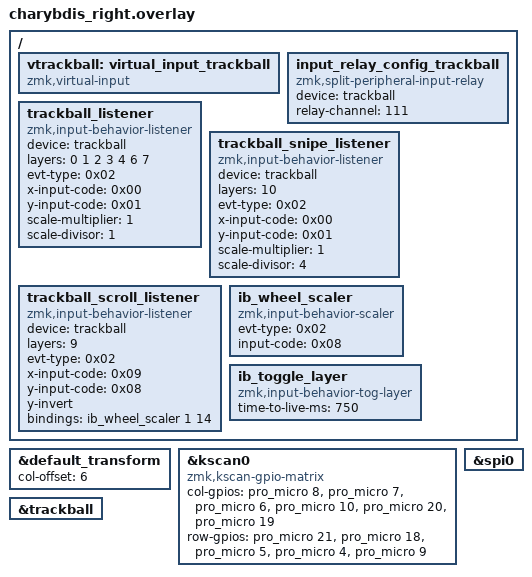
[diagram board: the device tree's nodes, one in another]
#include "charybdis.dtsi"
#include "charybdis_pmw3610.dtsi"

// The matrix transform is 6 columns over because the left half is 6 columns wide.
&default_transform {
	col-offset = <6>;
};

&kscan0 {
	compatible = "zmk,kscan-gpio-matrix";
	
	col-gpios
		= <&pro_micro 8 (GPIO_ACTIVE_HIGH | GPIO_PULL_DOWN)>
		, <&pro_micro 7 (GPIO_ACTIVE_HIGH | GPIO_PULL_DOWN)>
		, <&pro_micro 6 (GPIO_ACTIVE_HIGH | GPIO_PULL_DOWN)>
		, <&pro_micro 10 (GPIO_ACTIVE_HIGH | GPIO_PULL_DOWN)>
		, <&pro_micro 20 (GPIO_ACTIVE_HIGH | GPIO_PULL_DOWN)>
		, <&pro_micro 19 (GPIO_ACTIVE_HIGH | GPIO_PULL_DOWN)>
		;

	row-gpios
                = <&pro_micro 21  GPIO_ACTIVE_HIGH>
                , <&pro_micro 18  GPIO_ACTIVE_HIGH>
                , <&pro_micro 5  GPIO_ACTIVE_HIGH>
                , <&pro_micro 4  GPIO_ACTIVE_HIGH>
                , <&pro_micro 9 GPIO_ACTIVE_HIGH>
                ;
};

&spi0 {
    status = "okay";
};

&trackball {
    status = "okay";
};

// https://github.com/badjeff/zmk-pmw3610-driver
/ {
  vtrackball: virtual_input_trackball {
    compatible = "zmk,virtual-input";
  };

  // Relay trackball data to left side
  input_relay_config_trackball {
    compatible = "zmk,split-peripheral-input-relay";
    device = <&trackball>;
    relay-channel = <111>;
  };

  trackball_listener {
    compatible = "zmk,input-behavior-listener";
    device = <&trackball>;
    layers = <0 1 2 3 4 6 7>; // BASE LOWER SYMB NAV IDE QWERTY GAMING
    evt-type = <0x02>; // INPUT_EV_REL
    x-input-code = <0x00>; // INPUT_REL_X
    y-input-code = <0x01>; // INPUT_REL_Y
    scale-multiplier = <1>;
    scale-divisor = <1>;
  };

  trackball_snipe_listener {
    compatible = "zmk,input-behavior-listener";
    device = <&trackball>;
    layers = <10>; // SNIPE
    evt-type = <0x02>; // INPUT_EV_REL
    x-input-code = <0x00>; // INPUT_REL_X
    y-input-code = <0x01>; // INPUT_REL_Y
    scale-multiplier = <1>;
    scale-divisor = <4>;
  };

  trackball_scroll_listener {
    compatible = "zmk,input-behavior-listener";
    device = <&trackball>;
    layers = <9>; // SCROLL
    evt-type = <0x02>; // INPUT_EV_REL
    x-input-code = <0x09>; // INPUT_REL_MISC
    y-input-code = <0x08>; // INPUT_REL_WHEEL
    y-invert;
    bindings = <&ib_wheel_scaler 1 14>;
  };

  ib_wheel_scaler: ib_wheel_scaler {
    compatible = "zmk,input-behavior-scaler";
    #binding-cells = <2>;
    evt-type = <0x02>; // INPUT_EV_REL
    input-code = <0x08>; // INPUT_REL_WHEEL
  };

  ib_toggle_layer: ib_toggle_layer {
    compatible = "zmk,input-behavior-tog-layer";
    #binding-cells = <1>;
    time-to-live-ms = <750>;
  };
};
